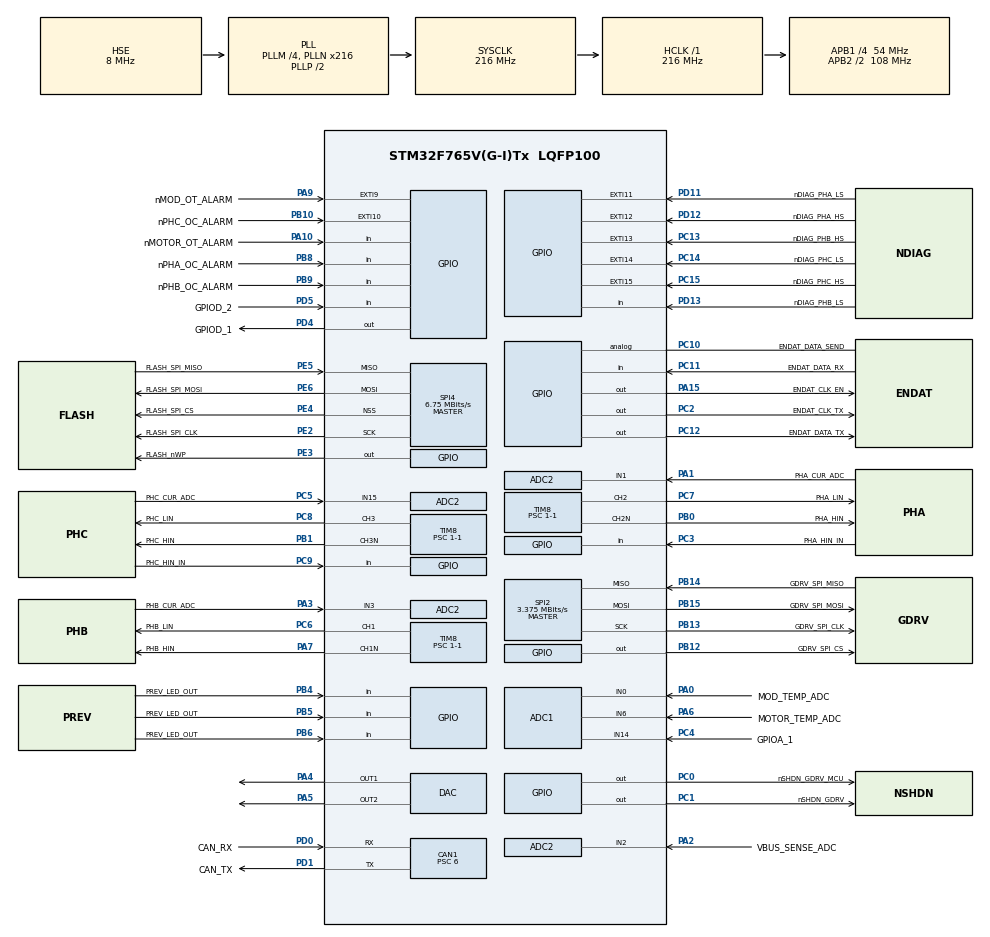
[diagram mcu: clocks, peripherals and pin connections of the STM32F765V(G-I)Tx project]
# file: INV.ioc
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ADC1.Channel-0\#ChannelRegularConversion=ADC_CHANNEL_0
ADC1.Channel-1\#ChannelRegularConversion=ADC_CHANNEL_6
ADC1.Channel-2\#ChannelRegularConversion=ADC_CHANNEL_14
ADC1.ClockPrescaler=ADC_CLOCK_SYNC_PCLK_DIV4
ADC1.ContinuousConvMode=DISABLE
ADC1.DMAContinuousRequests=ENABLE
ADC1.EOCSelection=ADC_EOC_SEQ_CONV
ADC1.ExternalTrigConv=ADC_EXTERNALTRIGCONV_T8_TRGO2
ADC1.InjNumberOfConversion=0
ADC1.NbrOfConversion=3
ADC1.NbrOfConversionFlag=1
ADC1.Rank-0\#ChannelRegularConversion=1
ADC1.Rank-1\#ChannelRegularConversion=2
ADC1.Rank-2\#ChannelRegularConversion=3
ADC1.SamplingTime-0\#ChannelRegularConversion=ADC_SAMPLETIME_15CYCLES
ADC1.SamplingTime-1\#ChannelRegularConversion=ADC_SAMPLETIME_15CYCLES
ADC1.SamplingTime-2\#ChannelRegularConversion=ADC_SAMPLETIME_15CYCLES
ADC1.ScanConvMode=ADC_SCAN_ENABLE
ADC1.master=1
ADC2.Channel-0\#ChannelRegularConversion=ADC_CHANNEL_1
ADC2.Channel-1\#ChannelRegularConversion=ADC_CHANNEL_3
ADC2.Channel-2\#ChannelRegularConversion=ADC_CHANNEL_15
ADC2.Channel-4\#ChannelRegularConversion=ADC_CHANNEL_2
ADC2.ClockPrescaler=ADC_CLOCK_SYNC_PCLK_DIV4
ADC2.ContinuousConvMode=DISABLE
ADC2.DMAContinuousRequests=ENABLE
ADC2.EOCSelection=ADC_EOC_SEQ_CONV
ADC2.ExternalTrigConv=ADC_EXTERNALTRIGCONV_T8_TRGO2
ADC2.NbrOfConversion=4
ADC2.NbrOfConversionFlag=1
ADC2.Rank-0\#ChannelRegularConversion=1
ADC2.Rank-1\#ChannelRegularConversion=2
ADC2.Rank-2\#ChannelRegularConversion=3
ADC2.Rank-4\#ChannelRegularConversion=4
ADC2.SamplingTime-0\#ChannelRegularConversion=ADC_SAMPLETIME_15CYCLES
ADC2.SamplingTime-1\#ChannelRegularConversion=ADC_SAMPLETIME_15CYCLES
ADC2.SamplingTime-2\#ChannelRegularConversion=ADC_SAMPLETIME_15CYCLES
ADC2.SamplingTime-4\#ChannelRegularConversion=ADC_SAMPLETIME_15CYCLES
ADC2.ScanConvMode=ADC_SCAN_ENABLE
CAN1.ABOM=ENABLE
CAN1.BS1=CAN_BS1_15TQ
CAN1.BS2=CAN_BS2_2TQ
CAN1.CalculateTimeQuantum=111.11111111111111
CAN1.NART=DISABLE
CAN1.Prescaler=6
CAN1.RFLM=ENABLE
CAN1.SJW=CAN_SJW_4TQ
CAN1.TXFP=ENABLE
CORTEX_M7.ART_ACCLERATOR_ENABLE=1
CORTEX_M7.CPU_DCache=Enabled
CORTEX_M7.CPU_ICache=Enabled
CORTEX_M7.PREFETCH_ENABLE=1
DAC.DAC_OutputBuffer=DAC_OUTPUTBUFFER_ENABLE
DAC.DAC_OutputBuffer2=DAC_OUTPUTBUFFER_ENABLE
Dma.ADC1.0.Direction=DMA_PERIPH_TO_MEMORY
Dma.ADC1.0.FIFOMode=DMA_FIFOMODE_DISABLE
Dma.ADC1.0.Instance=DMA2_Stream0
Dma.ADC1.0.MemDataAlignment=DMA_MDATAALIGN_HALFWORD
Dma.ADC1.0.MemInc=DMA_MINC_ENABLE
Dma.ADC1.0.Mode=DMA_CIRCULAR
Dma.ADC1.0.PeriphDataAlignment=DMA_PDATAALIGN_HALFWORD
Dma.ADC1.0.PeriphInc=DMA_PINC_DISABLE
Dma.ADC1.0.Priority=DMA_PRIORITY_LOW
Dma.ADC2.1.Direction=DMA_PERIPH_TO_MEMORY
Dma.ADC2.1.FIFOMode=DMA_FIFOMODE_DISABLE
Dma.ADC2.1.Instance=DMA2_Stream3
Dma.ADC2.1.MemDataAlignment=DMA_MDATAALIGN_HALFWORD
Dma.ADC2.1.MemInc=DMA_MINC_ENABLE
Dma.ADC2.1.Mode=DMA_CIRCULAR
Dma.ADC2.1.PeriphDataAlignment=DMA_PDATAALIGN_HALFWORD
Dma.ADC2.1.PeriphInc=DMA_PINC_DISABLE
Dma.ADC2.1.Priority=DMA_PRIORITY_LOW
Dma.Request0=ADC1
Dma.Request1=ADC2
Dma.Request2=TIM1_CH2
Dma.Request3=TIM1_CH3
Dma.TIM1_CH2.2.Direction=DMA_MEMORY_TO_PERIPH
Dma.TIM1_CH2.2.FIFOMode=DMA_FIFOMODE_DISABLE
Dma.TIM1_CH2.2.Instance=DMA2_Stream2
Dma.TIM1_CH2.2.MemDataAlignment=DMA_MDATAALIGN_WORD
Dma.TIM1_CH2.2.MemInc=DMA_MINC_ENABLE
Dma.TIM1_CH2.2.Mode=DMA_NORMAL
Dma.TIM1_CH2.2.PeriphDataAlignment=DMA_PDATAALIGN_WORD
Dma.TIM1_CH2.2.PeriphInc=DMA_PINC_DISABLE
Dma.TIM1_CH2.2.Priority=DMA_PRIORITY_HIGH
Dma.TIM1_CH3.3.Direction=DMA_PERIPH_TO_MEMORY
Dma.TIM1_CH3.3.FIFOMode=DMA_FIFOMODE_DISABLE
Dma.TIM1_CH3.3.Instance=DMA2_Stream6
Dma.TIM1_CH3.3.MemDataAlignment=DMA_MDATAALIGN_WORD
Dma.TIM1_CH3.3.MemInc=DMA_MINC_ENABLE
Dma.TIM1_CH3.3.Mode=DMA_NORMAL
Dma.TIM1_CH3.3.PeriphDataAlignment=DMA_PDATAALIGN_WORD
Dma.TIM1_CH3.3.PeriphInc=DMA_PINC_DISABLE
Dma.TIM1_CH3.3.Priority=DMA_PRIORITY_HIGH
FREERTOS.INCLUDE_uxTaskGetStackHighWaterMark=1
FREERTOS.INCLUDE_vTaskDelayUntil=1
FREERTOS.MEMORY_ALLOCATION=1
FREERTOS.Tasks01=Task1Hz,-2,512,RunTask1Hz,Default,NULL,Static,Task1HzTaskBuffer,Task1HzTaskControlBlock;Task1kHz,1,512,RunTask1kHz,Default,NULL,Static,TaskCan1kHzBuffer,TaskCan1kHzControlBlock;TaskCanRx,-3,512,RunTaskCanRx,Default,NULL,Static,TaskCanRxBuffer,TaskCanRxControlBlock;TaskCanTx,-3,512,RunTaskCanTx,Default,NULL,Static,TaskCanTxBuffer,TaskCanTxControlBlock;Task100Hz,-3,512,RunTask100Hz,Default,NULL,Static,Task100HzBuffer,Task100HzControlBlock
FREERTOS.configCHECK_FOR_STACK_OVERFLOW=2
FREERTOS.configMAX_TASK_NAME_LEN=32
FREERTOS.configUSE_TICK_HOOK=1
FREERTOS.configUSE_TRACE_FACILITY=1
IWDG.Reload=LSI_FREQUENCY / IWDG_PRESCALER / IWDG_RESET_FREQUENCY
IWDG.Window=IWDG_WINDOW_DISABLE_VALUE
Mcu.Family=STM32F7
Mcu.Name=STM32F765V(G-I)Tx
Mcu.Package=LQFP100
Mcu.UserConstants=TASK1HZ_STACK_SIZE,512;TASK1KHZ_STACK_SIZE,512;TASK100HZ_STACK_SIZE,512;TASKCANTX_STACK_SIZE,512;TASKCANRX_STACK_SIZE,512;IWDG_WINDOW_DISABLE_VALUE,4095;IWDG_PRESCALER,4;IWDG_RESET_FREQUENCY,5;LSI_FREQUENCY,32000;ADC1_NUM_CONVERSIONS,3;ADC2_NUM_CONVERSIONS,4;TASKCTRLLOOP_STACK_SIZE,512
NVIC.CAN1_RX0_IRQn=true\:5\:0\:false\:false\:true\:true\:true\:true
NVIC.CAN1_RX1_IRQn=true\:5\:0\:false\:false\:true\:true\:true\:true
NVIC.CAN1_TX_IRQn=true\:5\:0\:false\:false\:true\:true\:true\:true
NVIC.DMA2_Stream0_IRQn=true\:5\:0\:false\:false\:true\:true\:false\:true
NVIC.DMA2_Stream2_IRQn=true\:5\:0\:false\:false\:true\:true\:false\:true
NVIC.DMA2_Stream3_IRQn=true\:5\:0\:false\:false\:true\:false\:false\:true
NVIC.DMA2_Stream6_IRQn=true\:5\:0\:false\:false\:true\:true\:false\:true
NVIC.EXTI15_10_IRQn=true\:5\:0\:false\:false\:true\:true\:true\:true
NVIC.EXTI9_5_IRQn=true\:5\:0\:false\:false\:true\:true\:true\:true
NVIC.PriorityGroup=NVIC_PRIORITYGROUP_4
NVIC.TIM1_CC_IRQn=true\:5\:0\:false\:false\:true\:true\:true\:true
NVIC.TIM6_DAC_IRQn=true\:0\:0\:false\:false\:true\:false\:false\:true
NVIC.TIM8_UP_TIM13_IRQn=true\:5\:0\:false\:false\:true\:true\:true\:true
NVIC.TimeBase=TIM6_DAC_IRQn
NVIC.TimeBaseIP=TIM6
PA0/WKUP.GPIO_Label=MOD_TEMP_ADC
PA0/WKUP.Signal=ADCx_IN0
PA1.GPIO_Label=PHA_CUR_ADC
PA1.Signal=ADCx_IN1
PA10.GPIO_Label=nMOTOR_OT_ALARM
PA10.Signal=GPIO_Input
PA11.GPIO_Label=USB_DM
PA11.Signal=USB_OTG_FS_DM
PA12.GPIO_Label=USB_DP
PA12.Signal=USB_OTG_FS_DP
PA13.Mode=Trace_Asynchronous_SW
PA13.Signal=SYS_JTMS-SWDIO
PA14.Mode=Trace_Asynchronous_SW
PA14.Signal=SYS_JTCK-SWCLK
PA15.GPIO_Label=ENDAT_CLK_EN
PA15.Signal=GPIO_Output
PA2.GPIO_Label=VBUS_SENSE_ADC
PA2.Signal=ADCx_IN2
PA3.GPIO_Label=PHB_CUR_ADC
PA3.Signal=ADCx_IN3
PA4.Signal=COMP_DAC1_group
PA5.Signal=COMP_DAC2_group
PA6.GPIO_Label=MOTOR_TEMP_ADC
PA6.Signal=ADCx_IN6
PA7.GPIO_Label=PHB_HIN
PA7.Mode=PWM Generation1 CH1 CH1N
PA7.Signal=TIM8_CH1N
PA9.GPIO_Label=nMOD_OT_ALARM
PA9.GPIO_ModeDefaultEXTI=GPIO_MODE_IT_FALLING
PA9.Signal=GPXTI9
PB0.GPIO_Label=PHA_HIN
PB0.Mode=PWM Generation2 CH2 CH2N
PB0.Signal=TIM8_CH2N
PB1.GPIO_Label=PHC_HIN
PB1.Mode=PWM Generation3 CH3 CH3N
PB1.Signal=TIM8_CH3N
PB10.GPIO_Label=nPHC_OC_ALARM
PB10.Signal=GPXTI10
PB12.GPIO_Label=GDRV_SPI_CS
PB12.PinState=GPIO_PIN_SET
PB12.Signal=GPIO_Output
PB13.GPIO_Label=GDRV_SPI_CLK
PB13.Mode=Full_Duplex_Master
PB13.Signal=SPI2_SCK
PB14.GPIO_Label=GDRV_SPI_MISO
PB14.Mode=Full_Duplex_Master
PB14.Signal=SPI2_MISO
PB15.GPIO_Label=GDRV_SPI_MOSI
PB15.Mode=Full_Duplex_Master
PB15.Signal=SPI2_MOSI
PB3.Mode=Trace_Asynchronous_SW
PB3.Signal=SYS_JTDO-SWO
PB4.GPIO_Label=PREV_LED_OUT
PB4.Signal=GPIO_Input
PB5.GPIO_Label=PREV_LED_OUT
PB5.Signal=GPIO_Input
PB6.GPIO_Label=PREV_LED_OUT
PB6.Signal=GPIO_Input
PB8.GPIO_Label=nPHA_OC_ALARM
PB8.GPIO_PuPd=GPIO_PULLDOWN
PB8.Signal=GPIO_Input
PB9.GPIO_Label=nPHB_OC_ALARM
PB9.GPIO_PuPd=GPIO_PULLDOWN
PB9.Signal=GPIO_Input
PC0.GPIO_Label=nSHDN_GDRV_MCU
PC0.Signal=GPIO_Output
PC1.GPIO_Label=nSHDN_GDRV
PC1.PinState=GPIO_PIN_RESET
PC1.Signal=GPIO_Output
PC10.GPIO_Label=ENDAT_DATA_SEND
PC10.Signal=GPIO_Analog
PC11.GPIO_Label=ENDAT_DATA_RX
PC11.Signal=GPIO_Input
PC12.GPIO_Label=ENDAT_DATA_TX
PC12.Signal=GPIO_Output
PC13.GPIO_Label=nDIAG_PHB_HS
PC13.GPIO_PuPd=GPIO_PULLUP
PC13.Signal=GPXTI13
PC14/OSC32_IN.GPIO_Label=nDIAG_PHC_LS
PC14/OSC32_IN.GPIO_PuPd=GPIO_PULLUP
PC14/OSC32_IN.Signal=GPXTI14
PC15/OSC32_OUT.GPIO_Label=nDIAG_PHC_HS
PC15/OSC32_OUT.GPIO_PuPd=GPIO_PULLUP
PC15/OSC32_OUT.Signal=GPXTI15
PC2.GPIO_Label=ENDAT_CLK_TX
PC2.Signal=GPIO_Output
PC3.GPIO_Label=PHA_HIN_IN
PC3.Signal=GPIO_Input
PC4.GPIO_Label=GPIOA_1
PC4.Signal=ADCx_IN14
PC5.GPIO_Label=PHC_CUR_ADC
PC5.Signal=ADCx_IN15
PC6.GPIO_Label=PHB_LIN
PC6.Signal=S_TIM8_CH1
PC7.GPIO_Label=PHA_LIN
PC7.Signal=S_TIM8_CH2
PC8.GPIO_Label=PHC_LIN
PC8.Signal=S_TIM8_CH3
PC9.GPIO_Label=PHC_HIN_IN
PC9.Signal=GPIO_Input
PD0.GPIO_Label=CAN_RX
PD0.Mode=Master
PD0.Signal=CAN1_RX
PD1.GPIO_Label=CAN_TX
PD1.Mode=Master
PD1.Signal=CAN1_TX
PD11.GPIO_Label=nDIAG_PHA_LS
PD11.GPIO_PuPd=GPIO_PULLUP
PD11.Signal=GPXTI11
PD12.GPIO_Label=nDIAG_PHA_HS
PD12.GPIO_PuPd=GPIO_PULLUP
PD12.Signal=GPXTI12
PD13.GPIO_Label=nDIAG_PHB_LS
PD13.GPIO_PuPd=GPIO_PULLUP
PD13.Signal=GPIO_Input
PD4.GPIO_Label=GPIOD_1
PD4.Signal=GPIO_Output
PD5.GPIO_Label=GPIOD_2
PD5.Signal=GPIO_Input
PE2.GPIO_Label=FLASH_SPI_CLK
PE2.Mode=Full_Duplex_Master
PE2.Signal=SPI4_SCK
PE3.GPIO_Label=FLASH_nWP
PE3.Signal=GPIO_Output
PE4.GPIO_Label=FLASH_SPI_CS
PE4.Mode=NSS_Signal_Hard_Output
PE4.Signal=SPI4_NSS
PE5.GPIO_Label=FLASH_SPI_MISO
PE5.Mode=Full_Duplex_Master
PE5.Signal=SPI4_MISO
PE6.GPIO_Label=FLASH_SPI_MOSI
PE6.Mode=Full_Duplex_Master
PE6.Signal=SPI4_MOSI
PH0/OSC_IN.Mode=HSE-External-Oscillator
PH0/OSC_IN.Signal=RCC_OSC_IN
PH1/OSC_OUT.Mode=HSE-External-Oscillator
PH1/OSC_OUT.Signal=RCC_OSC_OUT
ProjectManager.HeapSize=0x200
ProjectManager.StackSize=0x400
ProjectManager.TargetToolchain=EWARM V8
RCC.AHBFreq_Value=216000000
RCC.APB1CLKDivider=RCC_HCLK_DIV4
RCC.APB1Freq_Value=54000000
RCC.APB1TimFreq_Value=108000000
RCC.APB2CLKDivider=RCC_HCLK_DIV2
RCC.APB2Freq_Value=108000000
RCC.APB2TimFreq_Value=216000000
RCC.CortexFreq_Value=216000000
RCC.HCLKFreq_Value=216000000
RCC.HSE_VALUE=8000000
RCC.HSI_VALUE=16000000
RCC.LSE_VALUE=32768
RCC.PLLM=4
RCC.PLLN=216
RCC.PLLQ=9
RCC.PLLSourceVirtual=RCC_PLLSOURCE_HSE
RCC.SYSCLKFreq_VALUE=216000000
RCC.SYSCLKSource=RCC_SYSCLKSOURCE_PLLCLK
RCC.USBFreq_Value=48000000
RCC.VCOOutputFreq_Value=432000000
SH.ADCx_IN0.0=ADC1_IN0,IN0
SH.ADCx_IN1.0=ADC2_IN1,IN1
SH.ADCx_IN14.0=ADC1_IN14,IN14
SH.ADCx_IN15.0=ADC2_IN15,IN15
SH.ADCx_IN2.0=ADC2_IN2,IN2
SH.ADCx_IN3.0=ADC2_IN3,IN3
SH.ADCx_IN6.0=ADC1_IN6,IN6
SH.COMP_DAC1_group.0=DAC_OUT1,DAC_OUT1
SH.COMP_DAC2_group.0=DAC_OUT2,DAC_OUT2
SH.S_TIM8_CH1.0=TIM8_CH1,PWM Generation1 CH1 CH1N
SH.S_TIM8_CH2.0=TIM8_CH2,PWM Generation2 CH2 CH2N
SH.S_TIM8_CH3.0=TIM8_CH3,PWM Generation3 CH3 CH3N
SPI2.BaudRatePrescaler=SPI_BAUDRATEPRESCALER_16
SPI2.CLKPhase=SPI_PHASE_2EDGE
SPI2.CRCCalculation=SPI_CRCCALCULATION_DISABLE
SPI2.CalculateBaudRate=3.375 MBits/s
SPI2.DataSize=SPI_DATASIZE_16BIT
SPI2.Direction=SPI_DIRECTION_2LINES
SPI2.Mode=SPI_MODE_MASTER
SPI2.VirtualType=VM_MASTER
SPI4.BaudRatePrescaler=SPI_BAUDRATEPRESCALER_16
SPI4.CalculateBaudRate=6.75 MBits/s
SPI4.DataSize=SPI_DATASIZE_16BIT
SPI4.Direction=SPI_DIRECTION_2LINES
SPI4.Mode=SPI_MODE_MASTER
SPI4.VirtualNSS=VM_NSSHARD
SPI4.VirtualType=VM_MASTER
TIM1.AutoReloadPreload=TIM_AUTORELOAD_PRELOAD_ENABLE
TIM1.Channel-Output\ Compare2\ No\ Output=TIM_CHANNEL_2
TIM1.Channel-Output\ Compare3\ No\ Output=TIM_CHANNEL_3
TIM1.OCMode_2=TIM_OCMODE_ACTIVE
TIM1.OCMode_3=TIM_OCMODE_ACTIVE
TIM1.Period=54-1
TIM1.Prescaler=1-1
TIM1.Pulse-Output\ Compare2\ No\ Output=27-1
TIM1.Pulse-Output\ Compare3\ No\ Output=27-1
TIM2.AutoReloadPreload=TIM_AUTORELOAD_PRELOAD_ENABLE
TIM2.Channel-Output\ Compare1\ No\ Output=TIM_CHANNEL_1
TIM2.Period=324000-1
TIM2.Prescaler=1-1
TIM8.AutoReloadPreload=TIM_AUTORELOAD_PRELOAD_ENABLE
TIM8.Channel-PWM\ Generation1\ CH1\ CH1N=TIM_CHANNEL_1
TIM8.Channel-PWM\ Generation2\ CH2\ CH2N=TIM_CHANNEL_2
TIM8.Channel-PWM\ Generation3\ CH3\ CH3N=TIM_CHANNEL_3
TIM8.Channel-PWM\ Generation4\ No\ Output=TIM_CHANNEL_4
TIM8.Channel-PWM\ Generation6\ No\ Output=TIM_CHANNEL_6
TIM8.CounterMode=TIM_COUNTERMODE_CENTERALIGNED1
TIM8.DeadTime=1
TIM8.OCMode_PWM-PWM\ Generation1\ CH1\ CH1N=TIM_OCMODE_PWM1
TIM8.OCMode_PWM-PWM\ Generation2\ CH2\ CH2N=TIM_OCMODE_PWM1
TIM8.OCMode_PWM-PWM\ Generation3\ CH3\ CH3N=TIM_OCMODE_PWM1
TIM8.OCMode_PWM-PWM\ Generation4\ No\ Output=TIM_OCMODE_PWM2
TIM8.OCMode_PWM-PWM\ Generation6\ No\ Output=TIM_OCMODE_PWM2
TIM8.Period=10800-1
TIM8.Prescaler=1-1
TIM8.Pulse-PWM\ Generation4\ No\ Output=10
TIM8.Pulse-PWM\ Generation6\ No\ Output=10
TIM8.RepetitionCounter=0
TIM8.TIM_MasterOutputTrigger=TIM_TRGO_RESET
TIM8.TIM_MasterOutputTrigger2=TIM_TRGO2_OC4REF_RISING_OC6REF_FALLING
VP_FREERTOS_VS_CMSIS_V1.Mode=CMSIS_V1
VP_IWDG_VS_IWDG.Mode=IWDG_Activate
VP_SYS_VS_tim6.Mode=TIM6
VP_TIM1_VS_ClockSourceINT.Mode=Internal
VP_TIM1_VS_no_output2.Mode=Output Compare2 No Output
VP_TIM1_VS_no_output3.Mode=Output Compare3 No Output
VP_TIM2_VS_ClockSourceINT.Mode=Internal
VP_TIM2_VS_no_output1.Mode=Output Compare1 No Output
VP_TIM8_VS_ClockSourceINT.Mode=Internal
VP_TIM8_VS_no_output4.Mode=PWM Generation4 No Output
VP_TIM8_VS_no_output6.Mode=PWM Generation6 No Output
board=custom

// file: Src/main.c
/* USER CODE BEGIN Header */
/**
 ******************************************************************************
 * @file           : main.c
 * @brief          : Main program body
 ******************************************************************************
 * @attention
 *
 * <h2><center>&copy; Copyright (c) 2020 STMicroelectronics.
 * All rights reserved.</center></h2>
 *
 * This software component is licensed by ST under BSD 3-Clause license,
 * the "License"; You may not use this file except in compliance with the
 * License. You may obtain a copy of the License at:
 *                        opensource.org/licenses/BSD-3-Clause
 *
 ******************************************************************************
 */
/* USER CODE END Header */

#include "main.h"
#include "cmsis_os.h"

/* USER CODE BEGIN Includes */
#include <assert.h>

#include "App_InvWorld.h"
#include "App_SharedStateMachine.h"
#include "App_GateDrive.h"
#include "App_Motor.h"
#include "App_PowerStage.h"
#include "states/App_InitState.h"
#include "states/App_DriveState.h"
#include "configs/App_HeartbeatMonitorConfig.h"

#include "Io_CanTx.h"
#include "Io_CanRx.h"
#include "Io_SoftwareWatchdog.h"
#include "Io_StackWaterMark.h"
#include "Io_SharedCan.h"
#include "Io_SharedErrorHandlerOverride.h"
#include "Io_SharedHardFaultHandler.h"
#include "Io_HeartbeatMonitor.h"
#include "Io_RgbLedSequence.h"
#include "Io_STGAP1AS.h"
#include "Io_TimerPwmGen.h"
#include "Io_AdcDac.h"
#include "Io_ECI1118.h"
#include "Io_PowerStage.h"
#include "control/App_ControlLoop.h"

/* USER CODE END Includes */

ADC_HandleTypeDef hadc1;
ADC_HandleTypeDef hadc2;
DMA_HandleTypeDef hdma_adc1;
DMA_HandleTypeDef hdma_adc2;

CAN_HandleTypeDef hcan1;

DAC_HandleTypeDef hdac;

IWDG_HandleTypeDef hiwdg;

SPI_HandleTypeDef hspi2;
SPI_HandleTypeDef hspi4;

TIM_HandleTypeDef htim1;
TIM_HandleTypeDef htim2;
TIM_HandleTypeDef htim8;
DMA_HandleTypeDef hdma_tim1_ch2;
DMA_HandleTypeDef hdma_tim1_ch3;

osThreadId          Task1HzHandle;
uint32_t            Task1HzTaskBuffer[512];
osStaticThreadDef_t Task1HzTaskControlBlock;
osThreadId          Task1kHzHandle;
uint32_t            TaskCan1kHzBuffer[512];
osStaticThreadDef_t TaskCan1kHzControlBlock;
osThreadId          TaskCanRxHandle;
uint32_t            TaskCanRxBuffer[512];
osStaticThreadDef_t TaskCanRxControlBlock;
osThreadId          TaskCanTxHandle;
uint32_t            TaskCanTxBuffer[512];
osStaticThreadDef_t TaskCanTxControlBlock;
osThreadId          Task100HzHandle;
uint32_t            Task100HzBuffer[512];
osStaticThreadDef_t Task100HzControlBlock;
/* USER CODE BEGIN PV */
struct InvWorld *         world;
struct StateMachine *     state_machine;
struct InvCanTxInterface *can_tx;
struct InvCanRxInterface *can_rx;
struct HeartbeatMonitor * heartbeat_monitor;
struct RgbLedSequence *   rgb_led_sequence;
struct ErrorTable *       error_table;
struct Clock *            clock;
struct PowerStage *       power_stage;
struct Motor *            motor;
struct GateDrive *        gate_drive;

static uint32_t adc_cal_startup_cycles = 0;
bool enable_gpio_exti_faults = 0;
/* USER CODE END PV */

void        SystemClock_Config(void);
static void MX_GPIO_Init(void);
static void MX_DMA_Init(void);
static void MX_ADC1_Init(void);
static void MX_ADC2_Init(void);
static void MX_CAN1_Init(void);
static void MX_DAC_Init(void);
static void MX_IWDG_Init(void);
static void MX_SPI2_Init(void);
static void MX_SPI4_Init(void);
static void MX_TIM8_Init(void);
static void MX_TIM1_Init(void);
static void MX_TIM2_Init(void);
void        RunTask1Hz(void const *argument);
void        RunTask1kHz(void const *argument);
void        RunTaskCanRx(void const *argument);
void        RunTaskCanTx(void const *argument);
void        RunTask100Hz(void const *argument);

/* USER CODE BEGIN 0 */
static void CanRxQueueOverflowCallBack(size_t overflow_count)
{
    App_CanTx_SetPeriodicSignal_RX_OVERFLOW_COUNT(can_tx, overflow_count);
}

static void CanTxQueueOverflowCallBack(size_t overflow_count)
{
    App_CanTx_SetPeriodicSignal_TX_OVERFLOW_COUNT(can_tx, overflow_count);
}
/* USER CODE END 0 */

int main(void)
{

    /* Enable I-Cache---------------------------------------------------------*/
    SCB_EnableICache();

    /* Enable D-Cache---------------------------------------------------------*/
    SCB_EnableDCache();

    /* MCU
     * Configuration--------------------------------------------------------*/

    /* Reset of all peripherals, Initializes the Flash interface and the
     * Systick. */
    HAL_Init();

    /* Configure the system clock */
    SystemClock_Config();

    /* Initialize all configured peripherals */
    MX_GPIO_Init();
    MX_DMA_Init();
    MX_ADC1_Init();
    MX_ADC2_Init();
    MX_CAN1_Init();
    MX_DAC_Init();
    MX_IWDG_Init();
    MX_SPI2_Init();
    MX_SPI4_Init();
    MX_TIM8_Init();
    MX_TIM1_Init();
    MX_TIM2_Init();
    /* USER CODE BEGIN 2 */

    __HAL_DBGMCU_FREEZE_IWDG();
    SEGGER_SYSVIEW_Conf();

    HAL_DMA_RegisterCallback(
        &hdma_tim1_ch2, HAL_DMA_XFER_CPLT_CB_ID,
        &Io_ECI1118_EncoderTransactionCompleteCallback);
    HAL_DMA_RegisterCallback(
        &hdma_tim1_ch3, HAL_DMA_XFER_CPLT_CB_ID, &HAL_DMA_IRQHandler);

    Io_ECI1118_Init();
    App_ControlLoop_SinCosLutInit();

    Io_SharedHardFaultHandler_Init();

    can_tx = App_CanTx_Create(
        Io_CanTx_EnqueueNonPeriodicMsg_INV_WATCHDOG_TIMEOUT,
        Io_CanTx_EnqueueNonPeriodicMsg_INV_AIR_SHUTDOWN_ERRORS);

    can_rx = App_CanRx_Create();

    heartbeat_monitor = App_SharedHeartbeatMonitor_Create(
        Io_HeartbeatMonitor_GetCurrentMs, HEARTBEAT_MONITOR_TIMEOUT_PERIOD_MS,
        HEARTBEAT_MONITOR_BOARDS_TO_CHECK, Io_HeartbeatMonitor_TimeoutCallback);

    rgb_led_sequence = App_SharedRgbLedSequence_Create(
        Io_RgbLedSequence_TurnOnRedLed, Io_RgbLedSequence_TurnOnBlueLed,
        Io_RgbLedSequence_TurnOnGreenLed);

    error_table = App_SharedErrorTable_Create();

    clock = App_SharedClock_Create();

    gate_drive = App_GateDrive_Create(
        Io_STGAP1AS_WriteConfiguration, Io_STGAP1AS_ResetStatus,
        Io_STGAP1AS_GlobalReset, Io_STGAP1AS_WriteRegister,
        Io_STGAP1AS_ReadRegister, Io_STGAP1AS_GetFaults, Io_STGAP1AS_Command,
        Io_STGAP1AS_SetShutdownPin, Io_STGAP1AS_GetShutdownPin,
        Io_TimerPwmGen_LoadPwm, Io_TimerPwmGen_StartPwmTimer,
        Io_TimerPwmGen_StopPwmTimer, Io_TimerPwmGen_SetSwitchingFreq,
        Io_TimerPwmGen_SetDeadTime, Io_STGAP1AS_GetPhaHiDiag,
        Io_STGAP1AS_GetPhaLoDiag, Io_STGAP1AS_GetPhbHiDiag,
        Io_STGAP1AS_GetPhbLoDiag, Io_STGAP1AS_GetPhcHiDiag,
        Io_STGAP1AS_GetPhcLoDiag);

    //        motor = App_Motor_Create(Io_ECI1118_GetTemperature,
    //        Io_ECI1118_GetRotorAngle);

    power_stage = App_PowerStage_Create(
        Io_AdcDac_AdcContModeInit, Io_AdcDac_AdcPwmSyncModeInit,
        Io_AdcDac_AdcStart, Io_AdcDac_AdcStop, Io_AdcDac_DacStart,
        Io_AdcDac_DacSetCurrentLim, Io_AdcDac_GetPhaseCurrents,
        Io_AdcDac_GetBusVoltage, Io_AdcDac_GetPowerstageTemp,
        Io_PowerStage_GetPhaOCFault, Io_PowerStage_GetPhbOCFault,
        Io_PowerStage_GetPhcOCFault, Io_PowerStage_GetOTFault);

    world = App_InvWorld_Create(
        can_tx, can_rx, heartbeat_monitor, rgb_led_sequence, error_table, clock,
        gate_drive, power_stage);

    state_machine = App_SharedStateMachine_Create(world, App_GetInitState());

    Io_StackWaterMark_Init(can_tx);
    Io_SoftwareWatchdog_Init(can_tx);

    //Delay 500ms after initialization to avoid power sequencing faults
    HAL_Delay(100);

    App_GateDrive_WriteConfig(gate_drive);

    App_PowerStage_Enable(power_stage); // Enable ADC

    App_GateDrive_StartPwmTimer(gate_drive);

    enable_gpio_exti_faults = 1;

    /* USER CODE END 2 */

    /* Create the thread(s) */
    /* definition and creation of Task1Hz */
    osThreadStaticDef(
        Task1Hz, RunTask1Hz, osPriorityLow, 0, 512, Task1HzTaskBuffer,
        &Task1HzTaskControlBlock);
    Task1HzHandle = osThreadCreate(osThread(Task1Hz), NULL);

    /* definition and creation of Task1kHz */
    osThreadStaticDef(
        Task1kHz, RunTask1kHz, osPriorityAboveNormal, 0, 512, TaskCan1kHzBuffer,
        &TaskCan1kHzControlBlock);
    Task1kHzHandle = osThreadCreate(osThread(Task1kHz), NULL);

    /* definition and creation of TaskCanRx */
    osThreadStaticDef(
        TaskCanRx, RunTaskCanRx, osPriorityIdle, 0, 512, TaskCanRxBuffer,
        &TaskCanRxControlBlock);
    TaskCanRxHandle = osThreadCreate(osThread(TaskCanRx), NULL);

    /* definition and creation of TaskCanTx */
    osThreadStaticDef(
        TaskCanTx, RunTaskCanTx, osPriorityIdle, 0, 512, TaskCanTxBuffer,
        &TaskCanTxControlBlock);
    TaskCanTxHandle = osThreadCreate(osThread(TaskCanTx), NULL);

    /* definition and creation of Task100Hz */
    osThreadStaticDef(
        Task100Hz, RunTask100Hz, osPriorityIdle, 0, 512, Task100HzBuffer,
        &Task100HzControlBlock);
    Task100HzHandle = osThreadCreate(osThread(Task100Hz), NULL);

    /* Start scheduler */
    osKernelStart();

    /* We should never get here as control is now taken by the scheduler */

    /* Infinite loop */
    while (1)
    {

    }
}

void SystemClock_Config(void)
{
    RCC_OscInitTypeDef RCC_OscInitStruct = { 0 };
    RCC_ClkInitTypeDef RCC_ClkInitStruct = { 0 };

    /** Configure the main internal regulator output voltage
     */
    __HAL_RCC_PWR_CLK_ENABLE();
    __HAL_PWR_VOLTAGESCALING_CONFIG(PWR_REGULATOR_VOLTAGE_SCALE1);
    /** Initializes the CPU, AHB and APB busses clocks
     */
    RCC_OscInitStruct.OscillatorType =
        RCC_OSCILLATORTYPE_LSI | RCC_OSCILLATORTYPE_HSE;
    RCC_OscInitStruct.HSEState      = RCC_HSE_ON;
    RCC_OscInitStruct.LSIState      = RCC_LSI_ON;
    RCC_OscInitStruct.PLL.PLLState  = RCC_PLL_ON;
    RCC_OscInitStruct.PLL.PLLSource = RCC_PLLSOURCE_HSE;
    RCC_OscInitStruct.PLL.PLLM      = 4;
    RCC_OscInitStruct.PLL.PLLN      = 216;
    RCC_OscInitStruct.PLL.PLLP      = RCC_PLLP_DIV2;
    RCC_OscInitStruct.PLL.PLLQ      = 9;
    if (HAL_RCC_OscConfig(&RCC_OscInitStruct) != HAL_OK)
    {
        Error_Handler();
    }
    /** Activate the Over-Drive mode
     */
    if (HAL_PWREx_EnableOverDrive() != HAL_OK)
    {
        Error_Handler();
    }
    /** Initializes the CPU, AHB and APB busses clocks
     */
    RCC_ClkInitStruct.ClockType = RCC_CLOCKTYPE_HCLK | RCC_CLOCKTYPE_SYSCLK |
                                  RCC_CLOCKTYPE_PCLK1 | RCC_CLOCKTYPE_PCLK2;
    RCC_ClkInitStruct.SYSCLKSource   = RCC_SYSCLKSOURCE_PLLCLK;
    RCC_ClkInitStruct.AHBCLKDivider  = RCC_SYSCLK_DIV1;
    RCC_ClkInitStruct.APB1CLKDivider = RCC_HCLK_DIV4;
    RCC_ClkInitStruct.APB2CLKDivider = RCC_HCLK_DIV2;

    if (HAL_RCC_ClockConfig(&RCC_ClkInitStruct, FLASH_LATENCY_7) != HAL_OK)
    {
        Error_Handler();
    }
}

static void MX_ADC1_Init(void)
{

    ADC_ChannelConfTypeDef sConfig = { 0 };

    /** Configure the global features of the ADC (Clock, Resolution, Data
     * Alignment and number of conversion)
     */
    hadc1.Instance                   = ADC1;
    hadc1.Init.ClockPrescaler        = ADC_CLOCK_SYNC_PCLK_DIV4;
    hadc1.Init.Resolution            = ADC_RESOLUTION_12B;
    hadc1.Init.ScanConvMode          = ADC_SCAN_ENABLE;
    hadc1.Init.ContinuousConvMode    = DISABLE;
    hadc1.Init.DiscontinuousConvMode = DISABLE;
    hadc1.Init.ExternalTrigConvEdge  = ADC_EXTERNALTRIGCONVEDGE_RISING;
    hadc1.Init.ExternalTrigConv      = ADC_EXTERNALTRIGCONV_T8_TRGO2;
    hadc1.Init.DataAlign             = ADC_DATAALIGN_RIGHT;
    hadc1.Init.NbrOfConversion       = 3;
    hadc1.Init.DMAContinuousRequests = ENABLE;
    hadc1.Init.EOCSelection          = ADC_EOC_SEQ_CONV;
    if (HAL_ADC_Init(&hadc1) != HAL_OK)
    {
        Error_Handler();
    }
    /** Configure for the selected ADC regular channel its corresponding rank in
     * the sequencer and its sample time.
     */
    sConfig.Channel      = ADC_CHANNEL_0;
    sConfig.Rank         = ADC_REGULAR_RANK_1;
    sConfig.SamplingTime = ADC_SAMPLETIME_15CYCLES;
    if (HAL_ADC_ConfigChannel(&hadc1, &sConfig) != HAL_OK)
    {
        Error_Handler();
    }
    /** Configure for the selected ADC regular channel its corresponding rank in
     * the sequencer and its sample time.
     */
    sConfig.Channel = ADC_CHANNEL_6;
    sConfig.Rank    = ADC_REGULAR_RANK_2;
    if (HAL_ADC_ConfigChannel(&hadc1, &sConfig) != HAL_OK)
    {
        Error_Handler();
    }
    /** Configure for the selected ADC regular channel its corresponding rank in
     * the sequencer and its sample time.
     */
    sConfig.Channel = ADC_CHANNEL_14;
    sConfig.Rank    = ADC_REGULAR_RANK_3;
    if (HAL_ADC_ConfigChannel(&hadc1, &sConfig) != HAL_OK)
    {
        Error_Handler();
    }
}

static void MX_ADC2_Init(void)
{

    ADC_ChannelConfTypeDef sConfig = { 0 };

    /** Configure the global features of the ADC (Clock, Resolution, Data
     * Alignment and number of conversion)
     */
    hadc2.Instance                   = ADC2;
    hadc2.Init.ClockPrescaler        = ADC_CLOCK_SYNC_PCLK_DIV4;
    hadc2.Init.Resolution            = ADC_RESOLUTION_12B;
    hadc2.Init.ScanConvMode          = ADC_SCAN_ENABLE;
    hadc2.Init.ContinuousConvMode    = DISABLE;
    hadc2.Init.DiscontinuousConvMode = DISABLE;
    hadc2.Init.ExternalTrigConvEdge  = ADC_EXTERNALTRIGCONVEDGE_RISING;
    hadc2.Init.ExternalTrigConv      = ADC_EXTERNALTRIGCONV_T8_TRGO2;
    hadc2.Init.DataAlign             = ADC_DATAALIGN_RIGHT;
    hadc2.Init.NbrOfConversion       = 4;
    hadc2.Init.DMAContinuousRequests = ENABLE;
    hadc2.Init.EOCSelection          = ADC_EOC_SEQ_CONV;
    if (HAL_ADC_Init(&hadc2) != HAL_OK)
    {
        Error_Handler();
    }
    /** Configure for the selected ADC regular channel its corresponding rank in
     * the sequencer and its sample time.
     */
    sConfig.Channel      = ADC_CHANNEL_1;
    sConfig.Rank         = ADC_REGULAR_RANK_1;
    sConfig.SamplingTime = ADC_SAMPLETIME_15CYCLES;
    if (HAL_ADC_ConfigChannel(&hadc2, &sConfig) != HAL_OK)
    {
        Error_Handler();
    }
    /** Configure for the selected ADC regular channel its corresponding rank in
     * the sequencer and its sample time.
     */
    sConfig.Channel = ADC_CHANNEL_3;
    sConfig.Rank    = ADC_REGULAR_RANK_2;
    if (HAL_ADC_ConfigChannel(&hadc2, &sConfig) != HAL_OK)
    {
        Error_Handler();
    }
    /** Configure for the selected ADC regular channel its corresponding rank in
     * the sequencer and its sample time.
     */
    sConfig.Channel = ADC_CHANNEL_15;
    sConfig.Rank    = ADC_REGULAR_RANK_3;
    if (HAL_ADC_ConfigChannel(&hadc2, &sConfig) != HAL_OK)
    {
        Error_Handler();
    }
    /** Configure for the selected ADC regular channel its corresponding rank in
     * the sequencer and its sample time.
     */
    sConfig.Channel = ADC_CHANNEL_2;
    sConfig.Rank    = ADC_REGULAR_RANK_4;
    if (HAL_ADC_ConfigChannel(&hadc2, &sConfig) != HAL_OK)
    {
        Error_Handler();
    }
}

static void MX_CAN1_Init(void)
{

    hcan1.Instance                  = CAN1;
    hcan1.Init.Prescaler            = 6;
    hcan1.Init.Mode                 = CAN_MODE_NORMAL;
    hcan1.Init.SyncJumpWidth        = CAN_SJW_4TQ;
    hcan1.Init.TimeSeg1             = CAN_BS1_15TQ;
    hcan1.Init.TimeSeg2             = CAN_BS2_2TQ;
    hcan1.Init.TimeTriggeredMode    = DISABLE;
    hcan1.Init.AutoBusOff           = ENABLE;
    hcan1.Init.AutoWakeUp           = DISABLE;
    hcan1.Init.AutoRetransmission   = DISABLE;
    hcan1.Init.ReceiveFifoLocked    = ENABLE;
    hcan1.Init.TransmitFifoPriority = ENABLE;
    if (HAL_CAN_Init(&hcan1) != HAL_OK)
    {
        Error_Handler();
    }
    /* USER CODE BEGIN CAN1_Init 2 */
    Io_SharedCan_Init(
        &hcan1, CanTxQueueOverflowCallBack, CanRxQueueOverflowCallBack);
    /* USER CODE END CAN1_Init 2 */
}

static void MX_DAC_Init(void)
{

    DAC_ChannelConfTypeDef sConfig = { 0 };

    /** DAC Initialization
     */
    hdac.Instance = DAC;
    if (HAL_DAC_Init(&hdac) != HAL_OK)
    {
        Error_Handler();
    }
    /** DAC channel OUT1 config
     */
    sConfig.DAC_Trigger      = DAC_TRIGGER_NONE;
    sConfig.DAC_OutputBuffer = DAC_OUTPUTBUFFER_ENABLE;
    if (HAL_DAC_ConfigChannel(&hdac, &sConfig, DAC_CHANNEL_1) != HAL_OK)
    {
        Error_Handler();
    }
    /** DAC channel OUT2 config
     */
    if (HAL_DAC_ConfigChannel(&hdac, &sConfig, DAC_CHANNEL_2) != HAL_OK)
    {
        Error_Handler();
    }
}

static void MX_IWDG_Init(void)
{

    hiwdg.Instance       = IWDG;
    hiwdg.Init.Prescaler = IWDG_PRESCALER_4;
    hiwdg.Init.Window    = IWDG_WINDOW_DISABLE_VALUE;
    hiwdg.Init.Reload = LSI_FREQUENCY / IWDG_PRESCALER / IWDG_RESET_FREQUENCY;
    if (HAL_IWDG_Init(&hiwdg) != HAL_OK)
    {
        Error_Handler();
    }
    /* USER CODE BEGIN IWDG_Init 2 */
    Io_SharedSoftwareWatchdog_Init(
        Io_HardwareWatchdog_Refresh, Io_SoftwareWatchdog_TimeoutCallback);
    /* USER CODE END IWDG_Init 2 */
}

static void MX_SPI2_Init(void)
{

    /* SPI2 parameter configuration*/
    hspi2.Instance               = SPI2;
    hspi2.Init.Mode              = SPI_MODE_MASTER;
    hspi2.Init.Direction         = SPI_DIRECTION_2LINES;
    hspi2.Init.DataSize          = SPI_DATASIZE_16BIT;
    hspi2.Init.CLKPolarity       = SPI_POLARITY_LOW;
    hspi2.Init.CLKPhase          = SPI_PHASE_2EDGE;
    hspi2.Init.NSS               = SPI_NSS_SOFT;
    hspi2.Init.BaudRatePrescaler = SPI_BAUDRATEPRESCALER_16;
    hspi2.Init.FirstBit          = SPI_FIRSTBIT_MSB;
    hspi2.Init.TIMode            = SPI_TIMODE_DISABLE;
    hspi2.Init.CRCCalculation    = SPI_CRCCALCULATION_DISABLE;
    hspi2.Init.CRCPolynomial     = 7;
    hspi2.Init.CRCLength         = SPI_CRC_LENGTH_DATASIZE;
    hspi2.Init.NSSPMode          = SPI_NSS_PULSE_DISABLE;
    if (HAL_SPI_Init(&hspi2) != HAL_OK)
    {
        Error_Handler();
    }
}

static void MX_SPI4_Init(void)
{

    /* SPI4 parameter configuration*/
    hspi4.Instance               = SPI4;
    hspi4.Init.Mode              = SPI_MODE_MASTER;
    hspi4.Init.Direction         = SPI_DIRECTION_2LINES;
    hspi4.Init.DataSize          = SPI_DATASIZE_16BIT;
    hspi4.Init.CLKPolarity       = SPI_POLARITY_LOW;
    hspi4.Init.CLKPhase          = SPI_PHASE_1EDGE;
    hspi4.Init.NSS               = SPI_NSS_HARD_OUTPUT;
    hspi4.Init.BaudRatePrescaler = SPI_BAUDRATEPRESCALER_16;
    hspi4.Init.FirstBit          = SPI_FIRSTBIT_MSB;
    hspi4.Init.TIMode            = SPI_TIMODE_DISABLE;
    hspi4.Init.CRCCalculation    = SPI_CRCCALCULATION_DISABLE;
    hspi4.Init.CRCPolynomial     = 7;
    hspi4.Init.CRCLength         = SPI_CRC_LENGTH_DATASIZE;
    hspi4.Init.NSSPMode          = SPI_NSS_PULSE_ENABLE;
    if (HAL_SPI_Init(&hspi4) != HAL_OK)
    {
        Error_Handler();
    }
}

static void MX_TIM1_Init(void)
{

    TIM_ClockConfigTypeDef         sClockSourceConfig   = { 0 };
    TIM_MasterConfigTypeDef        sMasterConfig        = { 0 };
    TIM_OC_InitTypeDef             sConfigOC            = { 0 };
    TIM_BreakDeadTimeConfigTypeDef sBreakDeadTimeConfig = { 0 };

    htim1.Instance               = TIM1;
    htim1.Init.Prescaler         = 1 - 1;
    htim1.Init.CounterMode       = TIM_COUNTERMODE_UP;
    htim1.Init.Period            = 54 - 1;
    htim1.Init.ClockDivision     = TIM_CLOCKDIVISION_DIV1;
    htim1.Init.RepetitionCounter = 0;
    htim1.Init.AutoReloadPreload = TIM_AUTORELOAD_PRELOAD_ENABLE;
    if (HAL_TIM_Base_Init(&htim1) != HAL_OK)
    {
        Error_Handler();
    }
    sClockSourceConfig.ClockSource = TIM_CLOCKSOURCE_INTERNAL;
    if (HAL_TIM_ConfigClockSource(&htim1, &sClockSourceConfig) != HAL_OK)
    {
        Error_Handler();
    }
    if (HAL_TIM_OC_Init(&htim1) != HAL_OK)
    {
        Error_Handler();
    }
    sMasterConfig.MasterOutputTrigger  = TIM_TRGO_RESET;
    sMasterConfig.MasterOutputTrigger2 = TIM_TRGO2_RESET;
    sMasterConfig.MasterSlaveMode      = TIM_MASTERSLAVEMODE_DISABLE;
    if (HAL_TIMEx_MasterConfigSynchronization(&htim1, &sMasterConfig) != HAL_OK)
    {
        Error_Handler();
    }
    sConfigOC.OCMode       = TIM_OCMODE_ACTIVE;
    sConfigOC.Pulse        = 27 - 1;
    sConfigOC.OCPolarity   = TIM_OCPOLARITY_HIGH;
    sConfigOC.OCNPolarity  = TIM_OCNPOLARITY_HIGH;
    sConfigOC.OCFastMode   = TIM_OCFAST_DISABLE;
    sConfigOC.OCIdleState  = TIM_OCIDLESTATE_RESET;
    sConfigOC.OCNIdleState = TIM_OCNIDLESTATE_RESET;
    if (HAL_TIM_OC_ConfigChannel(&htim1, &sConfigOC, TIM_CHANNEL_2) != HAL_OK)
    {
        Error_Handler();
    }
    if (HAL_TIM_OC_ConfigChannel(&htim1, &sConfigOC, TIM_CHANNEL_3) != HAL_OK)
    {
        Error_Handler();
    }
    sBreakDeadTimeConfig.OffStateRunMode  = TIM_OSSR_DISABLE;
    sBreakDeadTimeConfig.OffStateIDLEMode = TIM_OSSI_DISABLE;
    sBreakDeadTimeConfig.LockLevel        = TIM_LOCKLEVEL_OFF;
    sBreakDeadTimeConfig.DeadTime         = 0;
    sBreakDeadTimeConfig.BreakState       = TIM_BREAK_DISABLE;
    sBreakDeadTimeConfig.BreakPolarity    = TIM_BREAKPOLARITY_HIGH;
    sBreakDeadTimeConfig.BreakFilter      = 0;
    sBreakDeadTimeConfig.Break2State      = TIM_BREAK2_DISABLE;
    sBreakDeadTimeConfig.Break2Polarity   = TIM_BREAK2POLARITY_HIGH;
    sBreakDeadTimeConfig.Break2Filter     = 0;
    sBreakDeadTimeConfig.AutomaticOutput  = TIM_AUTOMATICOUTPUT_DISABLE;
    if (HAL_TIMEx_ConfigBreakDeadTime(&htim1, &sBreakDeadTimeConfig) != HAL_OK)
    {
        Error_Handler();
    }
}

static void MX_TIM2_Init(void)
{

    TIM_ClockConfigTypeDef  sClockSourceConfig = { 0 };
    TIM_MasterConfigTypeDef sMasterConfig      = { 0 };
    TIM_OC_InitTypeDef      sConfigOC          = { 0 };

    htim2.Instance               = TIM2;
    htim2.Init.Prescaler         = 1 - 1;
    htim2.Init.CounterMode       = TIM_COUNTERMODE_UP;
    htim2.Init.Period            = 324000 - 1;
    htim2.Init.ClockDivision     = TIM_CLOCKDIVISION_DIV1;
    htim2.Init.AutoReloadPreload = TIM_AUTORELOAD_PRELOAD_ENABLE;
    if (HAL_TIM_Base_Init(&htim2) != HAL_OK)
    {
        Error_Handler();
    }
    sClockSourceConfig.ClockSource = TIM_CLOCKSOURCE_INTERNAL;
    if (HAL_TIM_ConfigClockSource(&htim2, &sClockSourceConfig) != HAL_OK)
    {
        Error_Handler();
    }
    if (HAL_TIM_OC_Init(&htim2) != HAL_OK)
    {
        Error_Handler();
    }
    sMasterConfig.MasterOutputTrigger = TIM_TRGO_RESET;
    sMasterConfig.MasterSlaveMode     = TIM_MASTERSLAVEMODE_DISABLE;
    if (HAL_TIMEx_MasterConfigSynchronization(&htim2, &sMasterConfig) != HAL_OK)
    {
        Error_Handler();
    }
    sConfigOC.OCMode     = TIM_OCMODE_TIMING;
    sConfigOC.Pulse      = 0;
    sConfigOC.OCPolarity = TIM_OCPOLARITY_HIGH;
    sConfigOC.OCFastMode = TIM_OCFAST_DISABLE;
    if (HAL_TIM_OC_ConfigChannel(&htim2, &sConfigOC, TIM_CHANNEL_1) != HAL_OK)
    {
        Error_Handler();
    }
}

static void MX_TIM8_Init(void)
{

    TIM_ClockConfigTypeDef         sClockSourceConfig   = { 0 };
    TIM_MasterConfigTypeDef        sMasterConfig        = { 0 };
    TIM_OC_InitTypeDef             sConfigOC            = { 0 };
    TIM_BreakDeadTimeConfigTypeDef sBreakDeadTimeConfig = { 0 };

    htim8.Instance               = TIM8;
    htim8.Init.Prescaler         = 1 - 1;
    htim8.Init.CounterMode       = TIM_COUNTERMODE_CENTERALIGNED1;
    htim8.Init.Period            = 10800 - 1;
    htim8.Init.ClockDivision     = TIM_CLOCKDIVISION_DIV1;
    htim8.Init.RepetitionCounter = 0;
    htim8.Init.AutoReloadPreload = TIM_AUTORELOAD_PRELOAD_ENABLE;
    if (HAL_TIM_Base_Init(&htim8) != HAL_OK)
    {
        Error_Handler();
    }
    sClockSourceConfig.ClockSource = TIM_CLOCKSOURCE_INTERNAL;
    if (HAL_TIM_ConfigClockSource(&htim8, &sClockSourceConfig) != HAL_OK)
    {
        Error_Handler();
    }
    if (HAL_TIM_PWM_Init(&htim8) != HAL_OK)
    {
        Error_Handler();
    }
    sMasterConfig.MasterOutputTrigger  = TIM_TRGO_RESET;
    sMasterConfig.MasterOutputTrigger2 = TIM_TRGO2_OC4REF_RISING_OC6REF_FALLING;
    sMasterConfig.MasterSlaveMode      = TIM_MASTERSLAVEMODE_DISABLE;
    if (HAL_TIMEx_MasterConfigSynchronization(&htim8, &sMasterConfig) != HAL_OK)
    {
        Error_Handler();
    }
    sConfigOC.OCMode       = TIM_OCMODE_PWM1;
    sConfigOC.Pulse        = 0;
    sConfigOC.OCPolarity   = TIM_OCPOLARITY_HIGH;
    sConfigOC.OCNPolarity  = TIM_OCNPOLARITY_HIGH;
    sConfigOC.OCFastMode   = TIM_OCFAST_DISABLE;
    sConfigOC.OCIdleState  = TIM_OCIDLESTATE_RESET;
    sConfigOC.OCNIdleState = TIM_OCNIDLESTATE_RESET;
    if (HAL_TIM_PWM_ConfigChannel(&htim8, &sConfigOC, TIM_CHANNEL_1) != HAL_OK)
    {
        Error_Handler();
    }
    if (HAL_TIM_PWM_ConfigChannel(&htim8, &sConfigOC, TIM_CHANNEL_2) != HAL_OK)
    {
        Error_Handler();
    }
    if (HAL_TIM_PWM_ConfigChannel(&htim8, &sConfigOC, TIM_CHANNEL_3) != HAL_OK)
    {
        Error_Handler();
    }
    sConfigOC.OCMode = TIM_OCMODE_PWM2;
    sConfigOC.Pulse  = 10;
    if (HAL_TIM_PWM_ConfigChannel(&htim8, &sConfigOC, TIM_CHANNEL_4) != HAL_OK)
    {
        Error_Handler();
    }
    if (HAL_TIM_PWM_ConfigChannel(&htim8, &sConfigOC, TIM_CHANNEL_6) != HAL_OK)
    {
        Error_Handler();
    }
    sBreakDeadTimeConfig.OffStateRunMode  = TIM_OSSR_DISABLE;
    sBreakDeadTimeConfig.OffStateIDLEMode = TIM_OSSI_DISABLE;
    sBreakDeadTimeConfig.LockLevel        = TIM_LOCKLEVEL_OFF;
    sBreakDeadTimeConfig.DeadTime         = 1;
    sBreakDeadTimeConfig.BreakState       = TIM_BREAK_DISABLE;
    sBreakDeadTimeConfig.BreakPolarity    = TIM_BREAKPOLARITY_HIGH;
    sBreakDeadTimeConfig.BreakFilter      = 0;
    sBreakDeadTimeConfig.Break2State      = TIM_BREAK2_DISABLE;
    sBreakDeadTimeConfig.Break2Polarity   = TIM_BREAK2POLARITY_HIGH;
    sBreakDeadTimeConfig.Break2Filter     = 0;
    sBreakDeadTimeConfig.AutomaticOutput  = TIM_AUTOMATICOUTPUT_DISABLE;
    if (HAL_TIMEx_ConfigBreakDeadTime(&htim8, &sBreakDeadTimeConfig) != HAL_OK)
    {
        Error_Handler();
    }
    HAL_TIM_MspPostInit(&htim8);
}

static void MX_DMA_Init(void)
{
    /* DMA controller clock enable */
    __HAL_RCC_DMA2_CLK_ENABLE();

    /* DMA interrupt init */
    /* DMA2_Stream0_IRQn interrupt configuration */
    HAL_NVIC_SetPriority(DMA2_Stream0_IRQn, 5, 0);
    HAL_NVIC_EnableIRQ(DMA2_Stream0_IRQn);
    /* DMA2_Stream2_IRQn interrupt configuration */
    HAL_NVIC_SetPriority(DMA2_Stream2_IRQn, 5, 0);
    HAL_NVIC_EnableIRQ(DMA2_Stream2_IRQn);
    /* DMA2_Stream3_IRQn interrupt configuration */
    HAL_NVIC_SetPriority(DMA2_Stream3_IRQn, 5, 0);
    HAL_NVIC_EnableIRQ(DMA2_Stream3_IRQn);
    /* DMA2_Stream6_IRQn interrupt configuration */
    HAL_NVIC_SetPriority(DMA2_Stream6_IRQn, 5, 0);
    HAL_NVIC_EnableIRQ(DMA2_Stream6_IRQn);
}

static void MX_GPIO_Init(void)
{
    GPIO_InitTypeDef GPIO_InitStruct = { 0 };

    /* GPIO Ports Clock Enable */
    __HAL_RCC_GPIOE_CLK_ENABLE();
    __HAL_RCC_GPIOC_CLK_ENABLE();
    __HAL_RCC_GPIOH_CLK_ENABLE();
    __HAL_RCC_GPIOA_CLK_ENABLE();
    __HAL_RCC_GPIOB_CLK_ENABLE();
    __HAL_RCC_GPIOD_CLK_ENABLE();

    /*Configure GPIO pin Output Level */
    HAL_GPIO_WritePin(FLASH_nWP_GPIO_Port, FLASH_nWP_Pin, GPIO_PIN_RESET);

    /*Configure GPIO pin Output Level */
    HAL_GPIO_WritePin(
        GPIOC,
        nSHDN_GDRV_MCU_Pin | nSHDN_GDRV_Pin | ENDAT_CLK_TX_Pin |
            ENDAT_DATA_TX_Pin,
        GPIO_PIN_RESET);

    /*Configure GPIO pin Output Level */
    HAL_GPIO_WritePin(GDRV_SPI_CS_GPIO_Port, GDRV_SPI_CS_Pin, GPIO_PIN_SET);

    /*Configure GPIO pin Output Level */
    HAL_GPIO_WritePin(ENDAT_CLK_EN_GPIO_Port, ENDAT_CLK_EN_Pin, GPIO_PIN_RESET);

    /*Configure GPIO pin Output Level */
    HAL_GPIO_WritePin(GPIOD_1_GPIO_Port, GPIOD_1_Pin, GPIO_PIN_RESET);

    /*Configure GPIO pin : FLASH_nWP_Pin */
    GPIO_InitStruct.Pin   = FLASH_nWP_Pin;
    GPIO_InitStruct.Mode  = GPIO_MODE_OUTPUT_PP;
    GPIO_InitStruct.Pull  = GPIO_NOPULL;
    GPIO_InitStruct.Speed = GPIO_SPEED_FREQ_LOW;
    HAL_GPIO_Init(FLASH_nWP_GPIO_Port, &GPIO_InitStruct);

    /*Configure GPIO pins : nDIAG_PHB_HS_Pin nDIAG_PHC_LS_Pin nDIAG_PHC_HS_Pin
     */
    GPIO_InitStruct.Pin =
        nDIAG_PHB_HS_Pin | nDIAG_PHC_LS_Pin | nDIAG_PHC_HS_Pin;
    GPIO_InitStruct.Mode = GPIO_MODE_IT_RISING;
    GPIO_InitStruct.Pull = GPIO_PULLUP;
    HAL_GPIO_Init(GPIOC, &GPIO_InitStruct);

    /*Configure GPIO pins : nSHDN_GDRV_MCU_Pin nSHDN_GDRV_Pin ENDAT_CLK_TX_Pin
     * ENDAT_DATA_TX_Pin */
    GPIO_InitStruct.Pin = nSHDN_GDRV_MCU_Pin | nSHDN_GDRV_Pin |
                          ENDAT_CLK_TX_Pin | ENDAT_DATA_TX_Pin;
    GPIO_InitStruct.Mode  = GPIO_MODE_OUTPUT_PP;
    GPIO_InitStruct.Pull  = GPIO_NOPULL;
    GPIO_InitStruct.Speed = GPIO_SPEED_FREQ_LOW;
    HAL_GPIO_Init(GPIOC, &GPIO_InitStruct);

    /*Configure GPIO pins : PHA_HIN_IN_Pin PHC_HIN_IN_Pin ENDAT_DATA_RX_Pin */
    GPIO_InitStruct.Pin  = PHA_HIN_IN_Pin | PHC_HIN_IN_Pin | ENDAT_DATA_RX_Pin;
    GPIO_InitStruct.Mode = GPIO_MODE_INPUT;
    GPIO_InitStruct.Pull = GPIO_NOPULL;
    HAL_GPIO_Init(GPIOC, &GPIO_InitStruct);

    /*Configure GPIO pin : nPHC_OC_ALARM_Pin */
    GPIO_InitStruct.Pin  = nPHC_OC_ALARM_Pin;
    GPIO_InitStruct.Mode = GPIO_MODE_IT_RISING;
    GPIO_InitStruct.Pull = GPIO_NOPULL;
    HAL_GPIO_Init(nPHC_OC_ALARM_GPIO_Port, &GPIO_InitStruct);

    /*Configure GPIO pin : GDRV_SPI_CS_Pin */
    GPIO_InitStruct.Pin   = GDRV_SPI_CS_Pin;
    GPIO_InitStruct.Mode  = GPIO_MODE_OUTPUT_PP;
    GPIO_InitStruct.Pull  = GPIO_NOPULL;
    GPIO_InitStruct.Speed = GPIO_SPEED_FREQ_LOW;
    HAL_GPIO_Init(GDRV_SPI_CS_GPIO_Port, &GPIO_InitStruct);

    /*Configure GPIO pins : nDIAG_PHA_LS_Pin nDIAG_PHA_HS_Pin */
    GPIO_InitStruct.Pin  = nDIAG_PHA_LS_Pin | nDIAG_PHA_HS_Pin;
    GPIO_InitStruct.Mode = GPIO_MODE_IT_RISING;
    GPIO_InitStruct.Pull = GPIO_PULLUP;
    HAL_GPIO_Init(GPIOD, &GPIO_InitStruct);

    /*Configure GPIO pin : nDIAG_PHB_LS_Pin */
    GPIO_InitStruct.Pin  = nDIAG_PHB_LS_Pin;
    GPIO_InitStruct.Mode = GPIO_MODE_INPUT;
    GPIO_InitStruct.Pull = GPIO_PULLUP;
    HAL_GPIO_Init(nDIAG_PHB_LS_GPIO_Port, &GPIO_InitStruct);

    /*Configure GPIO pin : nMOD_OT_ALARM_Pin */
    GPIO_InitStruct.Pin  = nMOD_OT_ALARM_Pin;
    GPIO_InitStruct.Mode = GPIO_MODE_IT_FALLING;
    GPIO_InitStruct.Pull = GPIO_NOPULL;
    HAL_GPIO_Init(nMOD_OT_ALARM_GPIO_Port, &GPIO_InitStruct);

    /*Configure GPIO pin : nMOTOR_OT_ALARM_Pin */
    GPIO_InitStruct.Pin  = nMOTOR_OT_ALARM_Pin;
    GPIO_InitStruct.Mode = GPIO_MODE_INPUT;
    GPIO_InitStruct.Pull = GPIO_NOPULL;
    HAL_GPIO_Init(nMOTOR_OT_ALARM_GPIO_Port, &GPIO_InitStruct);

    /*Configure GPIO pins : USB_DM_Pin USB_DP_Pin */
    GPIO_InitStruct.Pin       = USB_DM_Pin | USB_DP_Pin;
    GPIO_InitStruct.Mode      = GPIO_MODE_AF_PP;
    GPIO_InitStruct.Pull      = GPIO_NOPULL;
    GPIO_InitStruct.Speed     = GPIO_SPEED_FREQ_VERY_HIGH;
    GPIO_InitStruct.Alternate = GPIO_AF10_OTG_FS;
    HAL_GPIO_Init(GPIOA, &GPIO_InitStruct);

    /*Configure GPIO pin : ENDAT_CLK_EN_Pin */
    GPIO_InitStruct.Pin   = ENDAT_CLK_EN_Pin;
    GPIO_InitStruct.Mode  = GPIO_MODE_OUTPUT_PP;
    GPIO_InitStruct.Pull  = GPIO_NOPULL;
    GPIO_InitStruct.Speed = GPIO_SPEED_FREQ_LOW;
    HAL_GPIO_Init(ENDAT_CLK_EN_GPIO_Port, &GPIO_InitStruct);

    /*Configure GPIO pin : ENDAT_DATA_SEND_Pin */
    GPIO_InitStruct.Pin  = ENDAT_DATA_SEND_Pin;
    GPIO_InitStruct.Mode = GPIO_MODE_ANALOG;
    GPIO_InitStruct.Pull = GPIO_NOPULL;
    HAL_GPIO_Init(ENDAT_DATA_SEND_GPIO_Port, &GPIO_InitStruct);

    /*Configure GPIO pin : GPIOD_1_Pin */
    GPIO_InitStruct.Pin   = GPIOD_1_Pin;
    GPIO_InitStruct.Mode  = GPIO_MODE_OUTPUT_PP;
    GPIO_InitStruct.Pull  = GPIO_NOPULL;
    GPIO_InitStruct.Speed = GPIO_SPEED_FREQ_LOW;
    HAL_GPIO_Init(GPIOD_1_GPIO_Port, &GPIO_InitStruct);

    /*Configure GPIO pin : GPIOD_2_Pin */
    GPIO_InitStruct.Pin  = GPIOD_2_Pin;
    GPIO_InitStruct.Mode = GPIO_MODE_INPUT;
    GPIO_InitStruct.Pull = GPIO_NOPULL;
    HAL_GPIO_Init(GPIOD_2_GPIO_Port, &GPIO_InitStruct);

    /*Configure GPIO pins : PREV_LED_OUT_Pin PREV_LED_OUTB5_Pin
     * PREV_LED_OUTB6_Pin */
    GPIO_InitStruct.Pin =
        PREV_LED_OUT_Pin | PREV_LED_OUTB5_Pin | PREV_LED_OUTB6_Pin;
    GPIO_InitStruct.Mode = GPIO_MODE_INPUT;
    GPIO_InitStruct.Pull = GPIO_NOPULL;
    HAL_GPIO_Init(GPIOB, &GPIO_InitStruct);

    /*Configure GPIO pins : nPHA_OC_ALARM_Pin nPHB_OC_ALARM_Pin */
    GPIO_InitStruct.Pin  = nPHA_OC_ALARM_Pin | nPHB_OC_ALARM_Pin;
    GPIO_InitStruct.Mode = GPIO_MODE_INPUT;
    GPIO_InitStruct.Pull = GPIO_PULLDOWN;
    HAL_GPIO_Init(GPIOB, &GPIO_InitStruct);

    /* EXTI interrupt init*/
    HAL_NVIC_SetPriority(EXTI9_5_IRQn, 5, 0);
    HAL_NVIC_EnableIRQ(EXTI9_5_IRQn);

    HAL_NVIC_SetPriority(EXTI15_10_IRQn, 5, 0);
    HAL_NVIC_EnableIRQ(EXTI15_10_IRQn);
}

/* USER CODE BEGIN 4 */
void HAL_ADC_ConvCpltCallback(ADC_HandleTypeDef *hadc)
{
    if (hadc->Instance == ADC1)
    {
    }
    if (hadc->Instance == ADC2)
    {
        if (adc_cal_startup_cycles < ADC_OFFSET_CAL_CYCLES + 1)
        {
            Io_AdcDac_CorrectPhaseCurOffset(adc_cal_startup_cycles);
            adc_cal_startup_cycles += 1;
        }

        SEGGER_SYSVIEW_RecordEnterISR();

        App_ControlLoop_Run(world);

        SEGGER_SYSVIEW_RecordExitISR();
    }
}

void HAL_GPIO_EXTI_Callback(uint16_t GPIO_Pin) {
    // TODO once board revision changes, commented pins will also be interrupt
    // triggered. Don't have the correct pins atm. asyncronously shut down the
    // gate drive if any fault pin interrupt is triggered

    // TODO this call to gatedrive shutdown leads to hard fault because this
    // interrupt gets executed before gate_drive is initialized
    // App_GateDrive_Shutdown(gate_drive);
    Io_STGAP1AS_SetShutdownPin(0);

    if (enable_gpio_exti_faults)
    {
        if (GPIO_Pin == nPHA_OC_ALARM_Pin) {
            App_CanTx_SetPeriodicSignal_PHA_OC_ALARM(can_tx, 1);
        } else if (GPIO_Pin == nPHB_OC_ALARM_Pin) {
            App_CanTx_SetPeriodicSignal_PHB_OC_ALARM(can_tx, 1);
        } else if (GPIO_Pin == nPHC_OC_ALARM_Pin) {
            App_CanTx_SetPeriodicSignal_PHC_OC_ALARM(can_tx, 1);
        }
            //    else if(GPIO_Pin == nMOD_OT_ALARM_Pin)
            //    {
            //        App_CanTx_SetPeriodicSignal_PWRSTG_OT_ALARM(can_tx, 1);
            //    }
            //    else if(GPIO_Pin == nMOTOR_OT_ALARM_Pin)
            //    {
            //        App_CanTx_SetPeriodicSignal_MOTOR_OT_ALARM(can_tx, 1);
            //    }
        else if (GPIO_Pin == nDIAG_PHA_LS_Pin) {
            App_CanTx_SetPeriodicSignal_PHA_LO_DIAG(can_tx, 1);
        } else if (GPIO_Pin == nDIAG_PHA_HS_Pin) {
            App_CanTx_SetPeriodicSignal_PHA_HI_DIAG(can_tx, 1);
        }
            //    else if(GPIO_Pin == nDIAG_PHB_LS_Pin)
            //    {
            //        App_CanTx_SetPeriodicSignal_PHB_LO_DIAG(can_tx, 1);
            //    }
        else if (GPIO_Pin == nDIAG_PHB_HS_Pin) {
            App_CanTx_SetPeriodicSignal_PHB_HI_DIAG(can_tx, 1);
        } else if (GPIO_Pin == nDIAG_PHC_LS_Pin) {
            App_CanTx_SetPeriodicSignal_PHC_LO_DIAG(can_tx, 1);
        } else if (GPIO_Pin == nDIAG_PHC_HS_Pin) {
            App_CanTx_SetPeriodicSignal_PHC_HI_DIAG(can_tx, 1);
        }
    }
}

/* USER CODE END 4 */

void RunTask1Hz(void const *argument)
{
    /* USER CODE BEGIN 5 */
    UNUSED(argument);
    uint32_t                 PreviousWakeTime = osKernelSysTick();
    static const TickType_t  period_ms        = 1000U;
    SoftwareWatchdogHandle_t watchdog =
        Io_SharedSoftwareWatchdog_AllocateWatchdog();
    Io_SharedSoftwareWatchdog_InitWatchdog(watchdog, TASK_1HZ, period_ms);
    for (;;)
    {
        App_SharedStateMachine_Tick1Hz(state_machine);
        Io_StackWaterMark_Check();
        // Watchdog check-in must be the last function called before putting the
        // task to sleep.
        Io_SharedSoftwareWatchdog_CheckInWatchdog(watchdog);
        osDelayUntil(&PreviousWakeTime, period_ms);
    }
    /* USER CODE END 5 */
}

void RunTask1kHz(void const *argument)
{
    /* USER CODE BEGIN RunTask1kHz */
    UNUSED(argument);
    uint32_t                 PreviousWakeTime = osKernelSysTick();
    static const TickType_t  period_ms        = 1;
    SoftwareWatchdogHandle_t watchdog =
        Io_SharedSoftwareWatchdog_AllocateWatchdog();
    Io_SharedSoftwareWatchdog_InitWatchdog(watchdog, TASK_1KHZ, period_ms);
    for (;;)
    {
        const uint32_t current_time_ms = osKernelSysTick() * portTICK_PERIOD_MS;
        App_SharedClock_SetCurrentTimeInMilliseconds(clock, current_time_ms);
        Io_CanTx_EnqueuePeriodicMsgs(can_tx, current_time_ms);
        // Watchdog check-in must be the last function called before putting the
        // task to sleep.
        Io_SharedSoftwareWatchdog_CheckInWatchdog(watchdog);
        Io_SharedSoftwareWatchdog_CheckForTimeouts();
        osDelayUntil(&PreviousWakeTime, period_ms);
    }
    /* USER CODE END RunTask1kHz */
}

void RunTaskCanRx(void const *argument)
{
    /* USER CODE BEGIN RunTaskCanRx */
    UNUSED(argument);
    for (;;)
    {
        struct CanMsg message;
        Io_SharedCan_DequeueCanRxMessage(&message);
        Io_CanRx_UpdateRxTableWithMessage(
            App_InvWorld_GetCanRx(world), &message);
    }
    /* USER CODE END RunTaskCanRx */
}

void RunTaskCanTx(void const *argument)
{
    /* USER CODE BEGIN RunTaskCanTx */
    UNUSED(argument);
    for (;;)
    {
        Io_SharedCan_TransmitEnqueuedCanTxMessagesFromTask();
    }
    /* USER CODE END RunTaskCanTx */
}

void RunTask100Hz(void const *argument)
{
    /* USER CODE BEGIN RunTask100Hz */
    UNUSED(argument);
    uint32_t                 PreviousWakeTime = osKernelSysTick();
    static const TickType_t  period_ms        = 10;
    SoftwareWatchdogHandle_t watchdog =
        Io_SharedSoftwareWatchdog_AllocateWatchdog();
    Io_SharedSoftwareWatchdog_InitWatchdog(watchdog, TASK_100HZ, period_ms);
    /* Infinite loop */
    for (;;)
    {
        App_SharedStateMachine_Tick100Hz(state_machine);
        // Watchdog check-in must be the last function called before putting the
        // task to sleep.
        Io_SharedSoftwareWatchdog_CheckInWatchdog(watchdog);
        osDelayUntil(&PreviousWakeTime, period_ms);
    }
    /* USER CODE END RunTask100Hz */
}

void HAL_TIM_PeriodElapsedCallback(TIM_HandleTypeDef *htim)
{
    /* USER CODE BEGIN Callback 0 */
    if (htim->Instance == TIM1)
    {
    }
    /* USER CODE END Callback 0 */
    if (htim->Instance == TIM6)
    {
        HAL_IncTick();
    }
    /* USER CODE BEGIN Callback 1 */
    if (htim->Instance == TIM8)
    {
        SEGGER_SYSVIEW_RecordEnterISR();

        SEGGER_SYSVIEW_RecordExitISR();
    }
    /* USER CODE END Callback 1 */
}

void Error_Handler(void)
{
    /* USER CODE BEGIN Error_Handler_Debug */
    __assert_func(file, line, "Error_Handler", "Error_Handler");
    /* USER CODE END Error_Handler_Debug */
}

#ifdef USE_FULL_ASSERT
/**
 * @brief  Reports the name of the source file and the source line number
 *         where the assert_param error has occurred.
 * @param  file: pointer to the source file name
 * @param  line: assert_param error line source number
 * @retval None
 */
void assert_failed(uint8_t *file, uint32_t line)
{
    /* USER CODE BEGIN 6 */
    __assert_func(file, line, "assert_failed", "assert_failed");
    /* USER CODE END 6 */
}
#endif /* USE_FULL_ASSERT */

/************************ (C) COPYRIGHT STMicroelectronics *****END OF FILE****/

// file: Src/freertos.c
/* USER CODE BEGIN Header */
/**
 ******************************************************************************
 * File Name          : freertos.c
 * Description        : Code for freertos applications
 ******************************************************************************
 * @attention
 *
 * <h2><center>&copy; Copyright (c) 2020 STMicroelectronics.
 * All rights reserved.</center></h2>
 *
 * This software component is licensed by ST under Ultimate Liberty license
 * SLA0044, the "License"; You may not use this file except in compliance with
 * the License. You may obtain a copy of the License at:
 *                             www.st.com/SLA0044
 *
 ******************************************************************************
 */
/* USER CODE END Header */

#include "FreeRTOS.h"
#include "task.h"
#include "main.h"

/* USER CODE BEGIN Includes */
#include "Io_SharedSoftwareWatchdog.h"
/* USER CODE END Includes */

/* GetIdleTaskMemory prototype (linked to static allocation support) */
void vApplicationGetIdleTaskMemory(
    StaticTask_t **ppxIdleTaskTCBBuffer,
    StackType_t ** ppxIdleTaskStackBuffer,
    uint32_t *     pulIdleTaskStackSize);

/* Hook prototypes */
void vApplicationTickHook(void);
void vApplicationStackOverflowHook(xTaskHandle xTask, signed char *pcTaskName);

/* USER CODE BEGIN 3 */
__weak void vApplicationTickHook(void)
{
    /* This function will be called by each tick interrupt if
    configUSE_TICK_HOOK is set to 1 in FreeRTOSConfig.h. User code can be
    added here, but the tick hook is called from an interrupt context, so
    code must not attempt to block, and only the interrupt safe FreeRTOS API
    functions can be used (those that end in FromISR()). */
    // Io_SharedSoftwareWatchdog_CheckForTimeouts();
}
/* USER CODE END 3 */

/* USER CODE BEGIN 4 */
__weak void
    vApplicationStackOverflowHook(xTaskHandle xTask, signed char *pcTaskName)
{
    (void)(xTask);
    (void)(pcTaskName);
    /* Run time stack overflow checking is performed if
    configCHECK_FOR_STACK_OVERFLOW is defined to 1 or 2. This hook function is
    called if a stack overflow is detected. */
}
/* USER CODE END 4 */

/* USER CODE BEGIN GET_IDLE_TASK_MEMORY */
static StaticTask_t xIdleTaskTCBBuffer;
static StackType_t  xIdleStack[configMINIMAL_STACK_SIZE];

void vApplicationGetIdleTaskMemory(
    StaticTask_t **ppxIdleTaskTCBBuffer,
    StackType_t ** ppxIdleTaskStackBuffer,
    uint32_t *     pulIdleTaskStackSize)
{
    *ppxIdleTaskTCBBuffer   = &xIdleTaskTCBBuffer;
    *ppxIdleTaskStackBuffer = &xIdleStack[0];
    *pulIdleTaskStackSize   = configMINIMAL_STACK_SIZE;
    /* place for user code */
}
/* USER CODE END GET_IDLE_TASK_MEMORY */

/************************ (C) COPYRIGHT STMicroelectronics *****END OF FILE****/
